# ISP6P5_GLBCE register map
Vendor: Texas Instruments
Registers are 32-bit, access per field, reset 0x0 unless marked. A register's access mark holds for its fields unless they carry their own. Offsets are as the file gives them; [hi:lo] are bit positions; 'fields as' and 'values as' point back to an identical list.

## ISP6P5_GLBCE (part 2 of 2)
0x00 GLBCE_CFG — GLBCE Configuration Registers
  [0] SWRST rw — This bit initiate software reset process
    0=OFF (SW Reset off or SW reset finished); 1=ON (SW reset start)
0x04 GLBCE_MODE
  [0] OST rw — One shot mode or continuous mode. One shot mode turns itself off after each frame. Note that this bit only controls the enable signal, and does not revert the statistics to the default status. To revert the cache content to the default status, you either need to SW reset GLBCE module, or load the default value from SDRAM to cache memory. To perform the latter option, default cache table needs to be copied to SDRAM before hand.
    0=CONTINUOUT (Continuous mode. GLBCE module keep running after each frame until the enable bit is turned off.); 1=ONE_SHOT (One shot mode. GLBCE turns off it self at the beginning of each frame.)
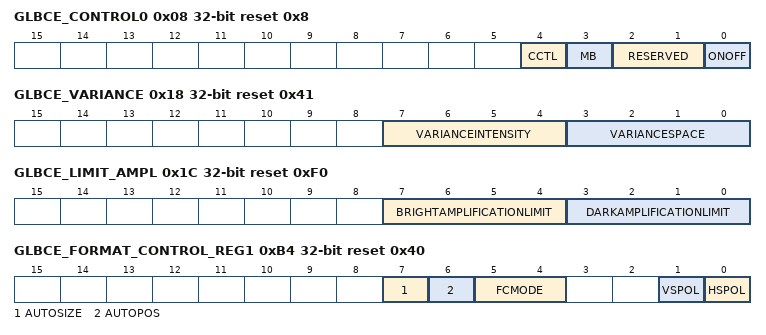
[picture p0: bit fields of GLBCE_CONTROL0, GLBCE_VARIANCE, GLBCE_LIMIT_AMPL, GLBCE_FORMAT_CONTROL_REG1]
0x08 GLBCE_CONTROL0 reset 0x8 — GLBCE Configuration Port GLBCE Control Register 0 (control_0)
  [4] CCTL ro — Color Control (CCTL) - Enabling this processing will result in more accurate colors processing. The color correction algorithm is required on gamma corrected sources It reduces the saturation in dark areas when they are being amplified, and saturates bright parts when they get darker. This bit is reserved and tied zero in ISS6 0b: Disable color correction 1b: Enable color correction
  [3] MB rw — Max Bayer Type- Use this bit to select the algorithm used for calculating intensity. 0b: Algorithm 1 1b: Algorithm 2 (Recommended)
    0=ALGORITHM1 (0b: Algorithm 1); 1=ALGORITHM2 (1b: Algorithm 2 (Recommended))
  [2:1] RESERVED ro — These bits are read only. Controls the storage of image sensor RAW data in memory. This bit is loaded with the timing of the internal VD signal: it becomes active starting at the lead of the VD signal that comes after 1 is written in this bit.
  [0] ONOFF rw — GLBCE On/Off - This bit turns GLBCE processing ON and OFF. When GLBCE is OFF, the video data passes to the output without any changes. Disabling GLBCE using this bit is equivalent to setting the Strength parameter to 0. Many internal modules run in idle mode when this bit is 0. The Latency Delays between the input and the output signals are the same in both ON and OFF modes. 0b: Disable GLBCE processing 1b: Enable GLBCE processing
    0=OFF (Disable); 1=ON (Enable)
0x0C GLBCE_CONTROL1 ro — GLBCE Configuration Port Reserved for future connection to CONTROL1 port Not used in OMAP6 as the port is not connected.
0x10 GLBCE_BLACK_LEVEL — GLBCE Configuration Port Black Level Register (black_level)
  [15:0] VAL rw — The value stored in Black Level Port will be used as zero level for GLBCE processing in all unsigned data channels. Data below Black level will not be processed and stay unchanged.
0x14 GLBCE_WHITE_LEVEL reset 0xFFFF — GLBCE Configuration Port White Level Register (white_level)
  [15:0] VAL rw — The value stored in White Level Port will be used as white level for GLBCE processing in all unsigned data channels. Data above White level will not be processed and stay unchanged.
0x18 GLBCE_VARIANCE reset 0x41 — GLBCE Configuration Port Affects the sensitivity of the transform to different areas of the image, and can be increased in order to emphasize small regions (e.g. faces). If this parameter is set to zero, the sensitivity to the small areas is maximal. The transform becomes more local. When the parameter is set to 0xFF the transform deemphasizes small local details, and transform becomes more global e.g. the sky at the top of the frame can affect flowers at the bottom of the frame.
  [7:4] VARIANCEINTENSITY rw — Variance Intensity - Sets the degree of sensitivity in the luminance domain. Maximum Variance is 0xF, and minimum Variance is 0x0.
  [3:0] VARIANCESPACE rw — Variance Space - Sets the degree of spatial sensitivity of the algorithm. As this parameter is made smaller, the algorithm focuses on smaller regions within the image. Maximum Variance is 0xF, and minimum Variance is 0x0.
0x1C GLBCE_LIMIT_AMPL reset 0xF0 — GLBCE Configuration Port The parameters ? dark amplification limit ? bright amplification limit are used to restrict the luminance space in which GLBCE can adaptively generate tone curves for each pixel.
  [7:4] BRIGHTAMPLIFICATIONLIMIT rw — Bright amplification limit - The resultant tone curve cannot be lower than bright amplification limit line controlled by the bright amplification limit parameter. See Chapter 4 of the spec document for more explanation. Maximum limit is 0xF, when the value is 0x0 there is no limit.
  [3:0] DARKAMPLIFICATIONLIMIT rw — Dark amplification limit - The resultant tone curve cannot be higher than dark amplification limit line controlled by the dark amplification limit parameter. See Chapter 4 of the spec for more explanation. Maximum limit is 0xF, when the value is 0x0 there is no limit.
0x20 GLBCE_DITHER — GLBCE Configuration Port Dithering Register (dither)
  [2:0] DITHER rw — 000b: No dithering 001b: One least significant bit of the output signal is dithered 010b: Two bits are dithered 011b: Three bits are dithered 100b: Four bits are dithered All other values : Four bits are dithered
    0=NO_DITHER (No dithering); 1=ONE_LSB (One least significant bit of the output signal is dithered); 3=THREE_LSBS (Three bits are dithered); 4=FOUR_LSBS (Four bits are dithered); 2=TWO_LSBS (Two bits are dithered)
0x24 GLBCE_SLOPE_MAX reset 0x28 — GLBCE Configuration Port Slope Max Limit Register (slope_max)
  [7:0] SLOPEMAXLIMIT rw — Slope Max Limit - Slope Max Limit is used to restrict the slope of the tone-curve generated by GLBCE. When Slope Max Limit parameter is set to 0xFF, the tone curve slope, generated by GLBCE is not limited (maximum slope 15). When this value is set to 00 GLBCE will not generate the tone-curve with slope greater than 16/15 (48?). Intermediate values of Slope Limit are linear interpolation between minimum and maximum values. Recommended Slope Max Limit range is 20h-60h. For noisy images less value should be used. See Chapter 4 of GLBCE datasheet for more explanation.
0x28 GLBCE_SLOPE_MIN reset 0x80 — GLBCE Configuration Port Slope Min Limit Register (slope_min)
  [7:0] SLOPEMINLIMIT rw — Slope Min Limit - Slope Min Limit is used to restrict the slope of the tone-curve generated by GLBCE. When Slope Min Limit parameter is set to 0x00, the tone curve slope, generated by GLBCE is not limited. When this value is set to FF GLBCE will not generate the tone-curve with slope less than 3/4. Intermediate values of Slope Limit are linear interpolation between minimum and maximum values. Recommended Slope Min Limit range is 00h-C0h. See Chapter 4 in GLBCE datasheet for more explanation.
0x2C GLBCE_LUT_FI_00 — GLBCE Configuration Port Asymmetry Function LUT The Asymmetry Function Lookup Table port geometry is 33 words, each of which is 16 bits. The Asymmetry function is used to balance the GLBCE effect between the dark and bright regions of the image.
  [15:0] VAL rw
0x30 GLBCE_LUT_FI_01 reset 0x1605 — GLBCE Configuration Port Asymmetry Function LUT The Asymmetry Function Lookup Table port geometry is 33 words, each of which is 16 bits. The Asymmetry function is used to balance the GLBCE effect between the dark and bright regions of the image.
  [15:0] VAL rw
0x34 GLBCE_LUT_FI_02 reset 0x29AE — GLBCE Configuration Port Asymmetry Function LUT The Asymmetry Function Lookup Table port geometry is 33 words, each of which is 16 bits. The Asymmetry function is used to balance the GLBCE effect between the dark and bright regions of the image.
  [15:0] VAL rw
0x38 GLBCE_LUT_FI_03 reset 0x3B59 — GLBCE Configuration Port Asymmetry Function LUT The Asymmetry Function Lookup Table port geometry is 33 words, each of which is 16 bits. The Asymmetry function is used to balance the GLBCE effect between the dark and bright regions of the image.
  [15:0] VAL rw
0x3C GLBCE_LUT_FI_04 reset 0x4B4E — GLBCE Configuration Port Asymmetry Function LUT The Asymmetry Function Lookup Table port geometry is 33 words, each of which is 16 bits. The Asymmetry function is used to balance the GLBCE effect between the dark and bright regions of the image.
  [15:0] VAL rw
0x40 GLBCE_LUT_FI_05 reset 0x59CA — GLBCE Configuration Port Asymmetry Function LUT The Asymmetry Function Lookup Table port geometry is 33 words, each of which is 16 bits. The Asymmetry function is used to balance the GLBCE effect between the dark and bright regions of the image.
  [15:0] VAL rw
0x44 GLBCE_LUT_FI_06 reset 0x6700 — GLBCE Configuration Port Asymmetry Function LUT The Asymmetry Function Lookup Table port geometry is 33 words, each of which is 16 bits. The Asymmetry function is used to balance the GLBCE effect between the dark and bright regions of the image.
  [15:0] VAL rw
0x48 GLBCE_LUT_FI_07 reset 0x7318 — GLBCE Configuration Port Asymmetry Function LUT The Asymmetry Function Lookup Table port geometry is 33 words, each of which is 16 bits. The Asymmetry function is used to balance the GLBCE effect between the dark and bright regions of the image.
  [15:0] VAL rw
0x4C GLBCE_LUT_FI_08 reset 0x7E36 — GLBCE Configuration Port Asymmetry Function LUT The Asymmetry Function Lookup Table port geometry is 33 words, each of which is 16 bits. The Asymmetry function is used to balance the GLBCE effect between the dark and bright regions of the image.
  [15:0] VAL rw
0x50 GLBCE_LUT_FI_09 reset 0x8875 — GLBCE Configuration Port Asymmetry Function LUT The Asymmetry Function Lookup Table port geometry is 33 words, each of which is 16 bits. The Asymmetry function is used to balance the GLBCE effect between the dark and bright regions of the image.
  [15:0] VAL rw
0x54 GLBCE_LUT_FI_10 reset 0x91F1 — GLBCE Configuration Port Asymmetry Function LUT The Asymmetry Function Lookup Table port geometry is 33 words, each of which is 16 bits. The Asymmetry function is used to balance the GLBCE effect between the dark and bright regions of the image.
  [15:0] VAL rw
0x58 GLBCE_LUT_FI_11 reset 0x9ABC — GLBCE Configuration Port Asymmetry Function LUT The Asymmetry Function Lookup Table port geometry is 33 words, each of which is 16 bits. The Asymmetry function is used to balance the GLBCE effect between the dark and bright regions of the image.
  [15:0] VAL rw
0x5C GLBCE_LUT_FI_12 reset 0xA2EB — GLBCE Configuration Port Asymmetry Function LUT The Asymmetry Function Lookup Table port geometry is 33 words, each of which is 16 bits. The Asymmetry function is used to balance the GLBCE effect between the dark and bright regions of the image.
  [15:0] VAL rw
0x60 GLBCE_LUT_FI_13 reset 0xAA8D — GLBCE Configuration Port Asymmetry Function LUT The Asymmetry Function Lookup Table port geometry is 33 words, each of which is 16 bits. The Asymmetry function is used to balance the GLBCE effect between the dark and bright regions of the image.
  [15:0] VAL rw
0x64 GLBCE_LUT_FI_14 reset 0xB1B0 — GLBCE Configuration Port Asymmetry Function LUT The Asymmetry Function Lookup Table port geometry is 33 words, each of which is 16 bits. The Asymmetry function is used to balance the GLBCE effect between the dark and bright regions of the image.
  [15:0] VAL rw
0x68 GLBCE_LUT_FI_15 reset 0xB85F — GLBCE Configuration Port Asymmetry Function LUT The Asymmetry Function Lookup Table port geometry is 33 words, each of which is 16 bits. The Asymmetry function is used to balance the GLBCE effect between the dark and bright regions of the image.
  [15:0] VAL rw
0x6C GLBCE_LUT_FI_16 reset 0xBEA5 — GLBCE Configuration Port Asymmetry Function LUT The Asymmetry Function Lookup Table port geometry is 33 words, each of which is 16 bits. The Asymmetry function is used to balance the GLBCE effect between the dark and bright regions of the image.
  [15:0] VAL rw
0x70 GLBCE_LUT_FI_17 reset 0xC48C — GLBCE Configuration Port Asymmetry Function LUT The Asymmetry Function Lookup Table port geometry is 33 words, each of which is 16 bits. The Asymmetry function is used to balance the GLBCE effect between the dark and bright regions of the image.
  [15:0] VAL rw
0x74 GLBCE_LUT_FI_18 reset 0xCA1C — GLBCE Configuration Port Asymmetry Function LUT The Asymmetry Function Lookup Table port geometry is 33 words, each of which is 16 bits. The Asymmetry function is used to balance the GLBCE effect between the dark and bright regions of the image.
  [15:0] VAL rw
0x78 GLBCE_LUT_FI_19 reset 0xCF5D — GLBCE Configuration Port Asymmetry Function LUT The Asymmetry Function Lookup Table port geometry is 33 words, each of which is 16 bits. The Asymmetry function is used to balance the GLBCE effect between the dark and bright regions of the image.
  [15:0] VAL rw
0x7C GLBCE_LUT_FI_20 reset 0xD454 — GLBCE Configuration Port Asymmetry Function LUT The Asymmetry Function Lookup Table port geometry is 33 words, each of which is 16 bits. The Asymmetry function is used to balance the GLBCE effect between the dark and bright regions of the image.
  [15:0] VAL rw
0x80 GLBCE_LUT_FI_21 reset 0xD907 — GLBCE Configuration Port Asymmetry Function LUT The Asymmetry Function Lookup Table port geometry is 33 words, each of which is 16 bits. The Asymmetry function is used to balance the GLBCE effect between the dark and bright regions of the image.
  [15:0] VAL rw
0x84 GLBCE_LUT_FI_22 reset 0xDD7C — GLBCE Configuration Port Asymmetry Function LUT The Asymmetry Function Lookup Table port geometry is 33 words, each of which is 16 bits. The Asymmetry function is used to balance the GLBCE effect between the dark and bright regions of the image.
  [15:0] VAL rw
0x88 GLBCE_LUT_FI_23 reset 0xE1B8 — GLBCE Configuration Port Asymmetry Function LUT The Asymmetry Function Lookup Table port geometry is 33 words, each of which is 16 bits. The Asymmetry function is used to balance the GLBCE effect between the dark and bright regions of the image.
  [15:0] VAL rw
0x8C GLBCE_LUT_FI_24 reset 0xE5BF — GLBCE Configuration Port Asymmetry Function LUT The Asymmetry Function Lookup Table port geometry is 33 words, each of which is 16 bits. The Asymmetry function is used to balance the GLBCE effect between the dark and bright regions of the image.
  [15:0] VAL rw
0x90 GLBCE_LUT_FI_25 reset 0xE994 — GLBCE Configuration Port Asymmetry Function LUT The Asymmetry Function Lookup Table port geometry is 33 words, each of which is 16 bits. The Asymmetry function is used to balance the GLBCE effect between the dark and bright regions of the image.
  [15:0] VAL rw
0x94 GLBCE_LUT_FI_26 reset 0xED3B — GLBCE Configuration Port Asymmetry Function LUT The Asymmetry Function Lookup Table port geometry is 33 words, each of which is 16 bits. The Asymmetry function is used to balance the GLBCE effect between the dark and bright regions of the image.
  [15:0] VAL rw
0x98 GLBCE_LUT_FI_27 reset 0xF0B7 — GLBCE Configuration Port Asymmetry Function LUT The Asymmetry Function Lookup Table port geometry is 33 words, each of which is 16 bits. The Asymmetry function is used to balance the GLBCE effect between the dark and bright regions of the image.
  [15:0] VAL rw
0x9C GLBCE_LUT_FI_28 reset 0xF40C — GLBCE Configuration Port Asymmetry Function LUT The Asymmetry Function Lookup Table port geometry is 33 words, each of which is 16 bits. The Asymmetry function is used to balance the GLBCE effect between the dark and bright regions of the image.
  [15:0] VAL rw
0xA0 GLBCE_LUT_FI_29 reset 0xF73B — GLBCE Configuration Port Asymmetry Function LUT The Asymmetry Function Lookup Table port geometry is 33 words, each of which is 16 bits. The Asymmetry function is used to balance the GLBCE effect between the dark and bright regions of the image.
  [15:0] VAL rw
0xA4 GLBCE_LUT_FI_30 reset 0xFA47 — GLBCE Configuration Port Asymmetry Function LUT The Asymmetry Function Lookup Table port geometry is 33 words, each of which is 16 bits. The Asymmetry function is used to balance the GLBCE effect between the dark and bright regions of the image.
  [15:0] VAL rw
0xA8 GLBCE_LUT_FI_31 reset 0xFD32 — GLBCE Configuration Port Asymmetry Function LUT The Asymmetry Function Lookup Table port geometry is 33 words, each of which is 16 bits. The Asymmetry function is used to balance the GLBCE effect between the dark and bright regions of the image.
  [15:0] VAL rw
0xAC GLBCE_LUT_FI_32 reset 0xFFFF — GLBCE Configuration Port Asymmetry Function LUT The Asymmetry Function Lookup Table port geometry is 33 words, each of which is 16 bits. The Asymmetry function is used to balance the GLBCE effect between the dark and bright regions of the image.
  [15:0] VAL rw
0xB0 GLBCE_FORMAT_CONTROL_REG0 ro — GLBCE Configuration Port The Data format port specifies the input data format so that the GLBCE core can process the different input data formats This register is reserved for ISS6.
  [1:0] DATAFORMAT — This value is reserved. The color format is always RGB, and this value should be fixed 0.
0xB4 GLBCE_FORMAT_CONTROL_REG1 ro reset 0x40 — GLBCE Configuration Port Control Reg1
  [7] AUTOSIZE — This value is read only. GLBCE in ISP6 nver use Auto-size mode.
    0=OFF (Auto size off. The GLBCE core will use frame_width, frame_height ports values.); 1=ON (Auto size on. The GLBCE core will calculate the frame geometry based on the active line and field signals. The size of current frame will be used for the estimation of the next frame. The Frame size will be updated when the Field signal toggles.)
  [6] AUTOPOS — This value is read only. GLBCE in ISP6 always runs in Auto Position mode.
    0=OFF (Auto Position off); 1=ON (Auto Position On)
  [5:4] FCMODE — Field Correction Mode
    0=INTERNAL (Internal field signal will be the same as external field signal. Internal generation of field is not available in this mode); 1=VSYNC (Adjust field signal with v_sync); 2=ACTIVELINE (Adjust field signal with active line)
  [1] VSPOL — Vertical Sync Polarity This value is read only. The SWITCH block always convert the polarity to rising edge active.
    0=RISING (Rising edge active); 1=FALLING (Falling edge active)
  [0] HSPOL — Horizontal Sync Polarity This value is read only. The SWITCH block always convert the polarity to rising edge active.
    values as VSPOL
0xB8 GLBCE_FRAME_WIDTH — GLBCE Configuration Port Frame Width is the number of pixels in an active line. This port is used only in ?non-automatic? mode.
  [15:0] VAL rw
0xBC GLBCE_FRAME_HEIGHT — GLBCE Configuration Port Frame Height is the number of active lines in one field.
  [15:0] VAL rw
0xC0 GLBCE_STRENGTH_IR reset 0x80 — GLBCE Configuration Port Strength (Strength of GLBCE) - This Port sets processing Strength. Minimum value is 0, maximum is 255.
  [7:0] VAL rw — 0x00: Video data will not be processed at all, and will go to the output unchanged. 0xFF: Maximum strength
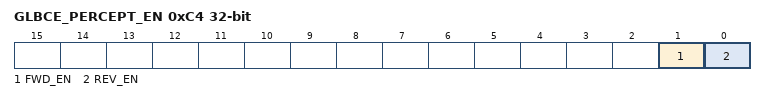
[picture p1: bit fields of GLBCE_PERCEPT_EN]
0xC4 GLBCE_PERCEPT_EN
  [1] FWD_EN rw
    0=DISABLE; 1=ENABLE
  [0] REV_EN rw — Reverse Perceptual LUT enable[
    0=DISABLE; 1=ENABLE
0xC8 GLBCE_REV_PERCEPT_LUT_00 — Reverse Perceptual LUT
  [15:0] VAL rw
0xCC GLBCE_REV_PERCEPT_LUT_01 reset 0xE4 — Reverse Perceptual LUT
  [15:0] VAL rw
0xD0 GLBCE_REV_PERCEPT_LUT_02 reset 0x1C7 — Reverse Perceptual LUT
  [15:0] VAL rw
0xD4 GLBCE_REV_PERCEPT_LUT_03 reset 0x2AB — Reverse Perceptual LUT
  [15:0] VAL rw
0xD8 GLBCE_REV_PERCEPT_LUT_04 reset 0x38E — Reverse Perceptual LUT
  [15:0] VAL rw
0xDC GLBCE_REV_PERCEPT_LUT_05 reset 0x472 — Reverse Perceptual LUT
  [15:0] VAL rw
0xE0 GLBCE_REV_PERCEPT_LUT_06 reset 0x559 — Reverse Perceptual LUT
  [15:0] VAL rw
0xE4 GLBCE_REV_PERCEPT_LUT_07 reset 0x65C — Reverse Perceptual LUT
  [15:0] VAL rw
0xE8 GLBCE_REV_PERCEPT_LUT_08 reset 0x778 — Reverse Perceptual LUT
  [15:0] VAL rw
0xEC GLBCE_REV_PERCEPT_LUT_09 reset 0x8AD — Reverse Perceptual LUT
  [15:0] VAL rw
0xF0 GLBCE_REV_PERCEPT_LUT_10 reset 0x9FC — Reverse Perceptual LUT
  [15:0] VAL rw
0xF4 GLBCE_REV_PERCEPT_LUT_11 reset 0xB64 — Reverse Perceptual LUT
  [15:0] VAL rw
0xF8 GLBCE_REV_PERCEPT_LUT_12 reset 0xCE8 — Reverse Perceptual LUT
  [15:0] VAL rw
0xFC GLBCE_REV_PERCEPT_LUT_13 reset 0xE85 — Reverse Perceptual LUT
  [15:0] VAL rw
0x100 GLBCE_REV_PERCEPT_LUT_14 reset 0x103E — Reverse Perceptual LUT
  [15:0] VAL rw
0x104 GLBCE_REV_PERCEPT_LUT_15 reset 0x1212 — Reverse Perceptual LUT
  [15:0] VAL rw
0x108 GLBCE_REV_PERCEPT_LUT_16 reset 0x1402 — Reverse Perceptual LUT
  [15:0] VAL rw
0x10C GLBCE_REV_PERCEPT_LUT_17 reset 0x160D — Reverse Perceptual LUT
  [15:0] VAL rw
0x110 GLBCE_REV_PERCEPT_LUT_18 reset 0x1835 — Reverse Perceptual LUT
  [15:0] VAL rw
0x114 GLBCE_REV_PERCEPT_LUT_19 reset 0x1A79 — Reverse Perceptual LUT
  [15:0] VAL rw
0x118 GLBCE_REV_PERCEPT_LUT_20 reset 0x1CDA — Reverse Perceptual LUT
  [15:0] VAL rw
0x11C GLBCE_REV_PERCEPT_LUT_21 reset 0x1F58 — Reverse Perceptual LUT
  [15:0] VAL rw
0x120 GLBCE_REV_PERCEPT_LUT_22 reset 0x21F3 — Reverse Perceptual LUT
  [15:0] VAL rw
0x124 GLBCE_REV_PERCEPT_LUT_23 reset 0x24AB — Reverse Perceptual LUT
  [15:0] VAL rw
0x128 GLBCE_REV_PERCEPT_LUT_24 reset 0x2781 — Reverse Perceptual LUT
  [15:0] VAL rw
0x12C GLBCE_REV_PERCEPT_LUT_25 reset 0x2A75 — Reverse Perceptual LUT
  [15:0] VAL rw
0x130 GLBCE_REV_PERCEPT_LUT_26 reset 0x2D86 — Reverse Perceptual LUT
  [15:0] VAL rw
0x134 GLBCE_REV_PERCEPT_LUT_27 reset 0x30B7 — Reverse Perceptual LUT
  [15:0] VAL rw
0x138 GLBCE_REV_PERCEPT_LUT_28 reset 0x3405 — Reverse Perceptual LUT
  [15:0] VAL rw
0x13C GLBCE_REV_PERCEPT_LUT_29 reset 0x3772 — Reverse Perceptual LUT
  [15:0] VAL rw
0x140 GLBCE_REV_PERCEPT_LUT_30 reset 0x3AFF — Reverse Perceptual LUT
  [15:0] VAL rw
0x144 GLBCE_REV_PERCEPT_LUT_31 reset 0x3EAA — Reverse Perceptual LUT
  [15:0] VAL rw
0x148 GLBCE_REV_PERCEPT_LUT_32 reset 0x4274 — Reverse Perceptual LUT
  [15:0] VAL rw
0x14C GLBCE_REV_PERCEPT_LUT_33 reset 0x465E — Reverse Perceptual LUT
  [15:0] VAL rw
0x150 GLBCE_REV_PERCEPT_LUT_34 reset 0x4A68 — Reverse Perceptual LUT
  [15:0] VAL rw
0x154 GLBCE_REV_PERCEPT_LUT_35 reset 0x4E91 — Reverse Perceptual LUT
  [15:0] VAL rw
0x158 GLBCE_REV_PERCEPT_LUT_36 reset 0x52DA — Reverse Perceptual LUT
  [15:0] VAL rw
0x15C GLBCE_REV_PERCEPT_LUT_37 reset 0x5744 — Reverse Perceptual LUT
  [15:0] VAL rw
0x160 GLBCE_REV_PERCEPT_LUT_38 reset 0x5BCD — Reverse Perceptual LUT
  [15:0] VAL rw
0x164 GLBCE_REV_PERCEPT_LUT_39 reset 0x6078 — Reverse Perceptual LUT
  [15:0] VAL rw
0x168 GLBCE_REV_PERCEPT_LUT_40 reset 0x6542 — Reverse Perceptual LUT
  [15:0] VAL rw
0x16C GLBCE_REV_PERCEPT_LUT_41 reset 0x6A2E — Reverse Perceptual LUT
  [15:0] VAL rw
0x170 GLBCE_REV_PERCEPT_LUT_42 reset 0x6F3B — Reverse Perceptual LUT
  [15:0] VAL rw
0x174 GLBCE_REV_PERCEPT_LUT_43 reset 0x7468 — Reverse Perceptual LUT
  [15:0] VAL rw
0x178 GLBCE_REV_PERCEPT_LUT_44 reset 0x79B7 — Reverse Perceptual LUT
  [15:0] VAL rw
0x17C GLBCE_REV_PERCEPT_LUT_45 reset 0x7F28 — Reverse Perceptual LUT
  [15:0] VAL rw
0x180 GLBCE_REV_PERCEPT_LUT_46 reset 0x84B9 — Reverse Perceptual LUT
  [15:0] VAL rw
0x184 GLBCE_REV_PERCEPT_LUT_47 reset 0x8A6D — Reverse Perceptual LUT
  [15:0] VAL rw
0x188 GLBCE_REV_PERCEPT_LUT_48 reset 0x9042 — Reverse Perceptual LUT
  [15:0] VAL rw
0x18C GLBCE_REV_PERCEPT_LUT_49 reset 0x963A — Reverse Perceptual LUT
  [15:0] VAL rw
0x190 GLBCE_REV_PERCEPT_LUT_50 reset 0x9C53 — Reverse Perceptual LUT
  [15:0] VAL rw
0x194 GLBCE_REV_PERCEPT_LUT_51 reset 0xA28F — Reverse Perceptual LUT
  [15:0] VAL rw
0x198 GLBCE_REV_PERCEPT_LUT_52 reset 0xA8ED — Reverse Perceptual LUT
  [15:0] VAL rw
0x19C GLBCE_REV_PERCEPT_LUT_53 reset 0xAF6E — Reverse Perceptual LUT
  [15:0] VAL rw
0x1A0 GLBCE_REV_PERCEPT_LUT_54 reset 0xB611 — Reverse Perceptual LUT
  [15:0] VAL rw
0x1A4 GLBCE_REV_PERCEPT_LUT_55 reset 0xBCD7 — Reverse Perceptual LUT
  [15:0] VAL rw
0x1A8 GLBCE_REV_PERCEPT_LUT_56 reset 0xC3C0 — Reverse Perceptual LUT
  [15:0] VAL rw
0x1AC GLBCE_REV_PERCEPT_LUT_57 reset 0xCACC — Reverse Perceptual LUT
  [15:0] VAL rw
0x1B0 GLBCE_REV_PERCEPT_LUT_58 reset 0xD1FB — Reverse Perceptual LUT
  [15:0] VAL rw
0x1B4 GLBCE_REV_PERCEPT_LUT_59 reset 0xD94E — Reverse Perceptual LUT
  [15:0] VAL rw
0x1B8 GLBCE_REV_PERCEPT_LUT_60 reset 0xE0C3 — Reverse Perceptual LUT
  [15:0] VAL rw
0x1BC GLBCE_REV_PERCEPT_LUT_61 reset 0xE85D — Reverse Perceptual LUT
  [15:0] VAL rw
0x1C0 GLBCE_REV_PERCEPT_LUT_62 reset 0xF01A — Reverse Perceptual LUT
  [15:0] VAL rw
0x1C4 GLBCE_REV_PERCEPT_LUT_63 reset 0xF7FA — Reverse Perceptual LUT
  [15:0] VAL rw
0x1C8 GLBCE_REV_PERCEPT_LUT_64 reset 0xFFFF — Reverse Perceptual LUT
  [15:0] VAL rw
0x1CC GLBCE_FWD_PERCEPT_LUT_00
  [15:0] VAL rw — Forward Perceptual LUT enable
0x1D0 GLBCE_FWD_PERCEPT_LUT_01 reset 0x120E
  [15:0] VAL rw — Forward Perceptual LUT enable
0x1D4 GLBCE_FWD_PERCEPT_LUT_02 reset 0x21CD
  [15:0] VAL rw — Forward Perceptual LUT enable
0x1D8 GLBCE_FWD_PERCEPT_LUT_03 reset 0x2DA4
  [15:0] VAL rw — Forward Perceptual LUT enable
0x1DC GLBCE_FWD_PERCEPT_LUT_04 reset 0x3773
  [15:0] VAL rw — Forward Perceptual LUT enable
0x1E0 GLBCE_FWD_PERCEPT_LUT_05 reset 0x3FFC
  [15:0] VAL rw — Forward Perceptual LUT enable
0x1E4 GLBCE_FWD_PERCEPT_LUT_06 reset 0x479F
  [15:0] VAL rw — Forward Perceptual LUT enable
0x1E8 GLBCE_FWD_PERCEPT_LUT_07 reset 0x4E96
  [15:0] VAL rw — Forward Perceptual LUT enable
0x1EC GLBCE_FWD_PERCEPT_LUT_08 reset 0x5506
  [15:0] VAL rw — Forward Perceptual LUT enable
0x1F0 GLBCE_FWD_PERCEPT_LUT_09 reset 0x5B08
  [15:0] VAL rw — Forward Perceptual LUT enable
0x1F4 GLBCE_FWD_PERCEPT_LUT_10 reset 0x60AF
  [15:0] VAL rw — Forward Perceptual LUT enable
0x1F8 GLBCE_FWD_PERCEPT_LUT_11 reset 0x6607
  [15:0] VAL rw — Forward Perceptual LUT enable
